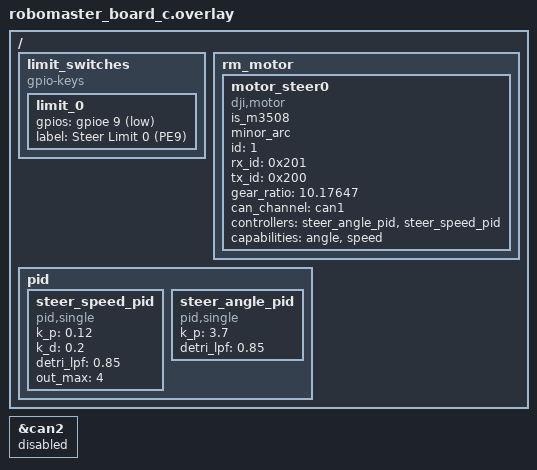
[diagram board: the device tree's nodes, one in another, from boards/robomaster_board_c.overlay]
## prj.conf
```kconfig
# 启用线程分析器
CONFIG_THREAD_ANALYZER=y
CONFIG_THREAD_ANALYZER_USE_LOG=y
CONFIG_THREAD_ANALYZER_USE_PRINTK=n
CONFIG_THREAD_NAME=y
# CONFIG_THREAD_ANALYZER_AUTO=y
# CONFIG_THREAD_ANALYZER_AUTO_INTERVAL=5
CONFIG_THREAD_ANALYZER_LOG_LEVEL_INF=y
CONFIG_THREAD_ANALYZER_AUTO_SEPARATE_CORES=n

# 启用 Shell 支持
CONFIG_SHELL=n
CONFIG_SHELL_BACKENDS=n
CONFIG_SHELL_BACKEND_SERIAL=n

# 启用 UART 控制台
CONFIG_UART_CONSOLE=y

# 禁用 SEGGER RTT
CONFIG_USE_SEGGER_RTT=n

# 启用事件支持
CONFIG_EVENTS=y

# 启用控制台支持
CONFIG_CONSOLE=y

# 启用日志系统
CONFIG_LOG=y
CONFIG_LOG_MODE_IMMEDIATE=y
CONFIG_LOG_PRINTK=y
CONFIG_LOG_BACKEND_UART=y
# CONFIG_LOG_MODE_IMMEDIATE=y

# 启用串行支持
CONFIG_SERIAL=y

# 禁用优化
CONFIG_NO_OPTIMIZATIONS=n

# 启用驱动
CONFIG_MOTOR=y
CONFIG_MOTOR_DJI=y
CONFIG_MOTOR_LOG_LEVEL=4
CONFIG_CAN=y
CONFIG_MOTOR_INIT_PRIORITY=90

CONFIG_ARES=y
CONFIG_ARES_SBUS=y
CONFIG_EKF_LIB=y
CONFIG_VOFA_LIB=y

CONFIG_AUTO_PROBE_GYRO_BIAS=y

# use ASYNC uart API
CONFIG_SERIAL=y
CONFIG_UART_ASYNC_API=y
CONFIG_UART_INTERRUPT_DRIVEN=y

CONFIG_DMA=y
CONFIG_DMA_STM32=y  # STM32 DMA 驱动
CONFIG_UART_STM32=y # STM32 UART 驱动
# CONFIG_STM32_UART_DMA=y

# CONFIG_HAS_STM32CUBE=y
# CONFIG_USE_STM32_HAL_DMA=y
CONFIG_SPI=y
CONFIG_SPI_STM32=y

CONFIG_CMSIS_DSP=y
CONFIG_CMSIS_DSP_MATRIX=y
CONFIG_CMSIS_DSP_CONTROLLER=y
CONFIG_CMSIS_DSP_FASTMATH=y

CONFIG_ZBUS=y
CONFIG_ZBUS_LOG_LEVEL_OFF=y
CONFIG_ZBUS_MSG_SUBSCRIBER=y
CONFIG_ZBUS_RUNTIME_OBSERVERS=y
```

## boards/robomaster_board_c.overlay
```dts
/ {
    limit_switches {
        compatible = "gpio-keys";
        limit_0: limit_0 {
            gpios = <&gpioe 9 (GPIO_ACTIVE_LOW | GPIO_PULL_UP)>;
            label = "Steer Limit 0 (PE9)";
        };
    };

    rm_motor {
        motor_steer0: motor_steer0 {
            compatible = "dji,motor";
            is_m3508;
            minor_arc; 
            id = <1>;
            rx_id = <0x201>;
            tx_id = <0x200>;
            gear_ratio = "10.17647"; // 173 / 17
            status = "okay";
            can_channel = <&can1>;
            controllers = <&steer_angle_pid &steer_speed_pid>;
            capabilities = "angle", "speed";
        };
    };

    pid {
        /* 3508 速度环 */
        steer_speed_pid: steer_speed_pid {
            #controller-cells = <0>;
			compatible = "pid,single";
			k_p = "0.12";
			k_d = "0.2";
			detri_lpf = "0.85";
			out_max = "4";
        };

        /* 3508 角度环 */
        steer_angle_pid: steer_angle_pid {
            #controller-cells = <0>;
			compatible = "pid,single";
			k_p = "3.7";
			detri_lpf = "0.85";
        };
    };
};

&can2 {
    status = "disabled";
};
```

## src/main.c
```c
/*
 * Copyright (c) 2024 ttwards <12411711@mail.sustech.edu.cn>
 *
 * SPDX-License-Identifier: Apache-2.0
 */

#include <math.h>
#include <zephyr/kernel.h>
#include <zephyr/device.h>
#include <zephyr/drivers/gpio.h>
#include <zephyr/drivers/motor.h>
#include <zephyr/logging/log.h>
#include <ares/board/init.h>
#include "devices.h"

LOG_MODULE_REGISTER(homing_test, LOG_LEVEL_INF);

static const struct gpio_dt_spec limit_0 = GPIO_DT_SPEC_GET(DT_NODELABEL(limit_0), gpios);

int main(void)
{
    board_init();

    k_sleep(K_MSEC(2000));
    LOG_INF("单舵轮 (steer_motor1) 光电门寻零测试");

    if (!device_is_ready(limit_0.port)) {
        LOG_ERR("光电门未就绪！");
        return -1;
    }
    gpio_pin_configure_dt(&limit_0, GPIO_INPUT);

    if (!device_is_ready(steer_motor1)) {
        LOG_ERR("舵向电机未就绪！");
        return -1;
    }

    motor_control(steer_motor1, ENABLE_MOTOR);
    LOG_INF("舵向电机已使能 (ENABLE_MOTOR)");

    LOG_INF("[准备阶段] 初始状态确认...");
    if (gpio_pin_get_dt(&limit_0) == 1) {
        LOG_WRN("开机时铁片在光电门内！后退退出...");
        motor_set_speed(steer_motor1, -25.0f);
        while (gpio_pin_get_dt(&limit_0) == 1) {
            k_msleep(5);
        }
        k_msleep(150); 
    }

    LOG_INF("[阶段 1] 快速寻找光电门 (60 RPM)...");
    motor_set_speed(steer_motor1, 60.0f);
    while (true) {
        if (gpio_pin_get_dt(&limit_0) == 1) {
            LOG_INF("-> 光电门已触发！");
            break;
        }
        k_msleep(5);
    }

    LOG_INF("[阶段 2] 反转退出光电门 (-25 RPM)...");
    motor_set_speed(steer_motor1, -25.0f);
    while (true) {
        if (gpio_pin_get_dt(&limit_0) == 0) {
            k_msleep(150); 
            break;
        }
        k_msleep(5);
    }

    LOG_INF("[阶段 3] 极慢速精确切入 (5 RPM)...");
    motor_set_speed(steer_motor1, 5.0f);
    while (true) {
        if (gpio_pin_get_dt(&limit_0) == 1) {
            k_msleep(2);
            if (gpio_pin_get_dt(&limit_0) == 1) {
                motor_set_speed(steer_motor1, 0.0f);
                k_msleep(50); 
                
                motor_control(steer_motor1, SET_ZERO);
                LOG_INF("寻零完美锁定！");
                break;
            }
        }
        k_msleep(2);
    }

    k_msleep(100);
    LOG_INF("切换至位置环，死守目标角度: 0.0度");
    motor_set_angle(steer_motor1, 0.0f);

    motor_status_t status;
    while (1) {
        if (motor_get(steer_motor1, &status) == 0) {
            LOG_INF("angle: %7.2f° | speed: %6.1f RPM | torque: %5.2f | limit_0: %s", 
                    status.angle, status.rpm, status.torque,
                    gpio_pin_get_dt(&limit_0) ? "1" : "0");
        }
        k_sleep(K_MSEC(500));
    }
    return 0;
}
```

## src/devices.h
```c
#ifndef DEVICES_H
#define DEVICES_H

#include <zephyr/device.h>
#include <zephyr/drivers/gpio.h>

#define STEERMOTOR1_NODE    DT_NODELABEL(motor_steer0)
#define LIMIT0_NODE         DT_NODELABEL(limit_0)

/* 导出设备指针 */
static const struct device *steer_motor1 = DEVICE_DT_GET(STEERMOTOR1_NODE);

#endif /* DEVICES_H */
```
